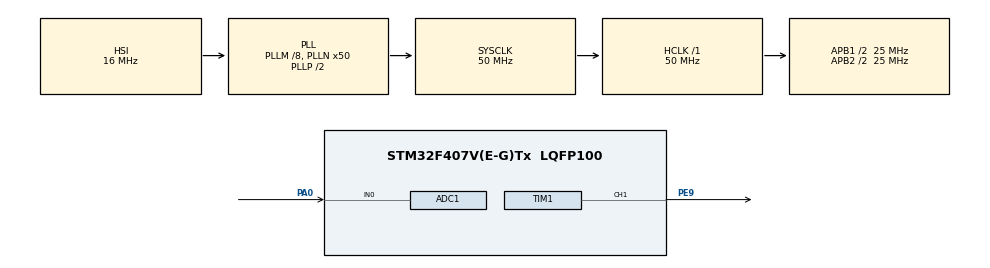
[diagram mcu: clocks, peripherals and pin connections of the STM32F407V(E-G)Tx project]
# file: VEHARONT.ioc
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ADC1.Channel-5\#ChannelRegularConversion=ADC_CHANNEL_0
ADC1.NbrOfConversionFlag=1
ADC1.Rank-5\#ChannelRegularConversion=1
ADC1.SamplingTime-5\#ChannelRegularConversion=ADC_SAMPLETIME_3CYCLES
ADC1.master=1
Mcu.Family=STM32F4
Mcu.Name=STM32F407V(E-G)Tx
Mcu.Package=LQFP100
NVIC.PriorityGroup=NVIC_PRIORITYGROUP_0
PA0-WKUP.Signal=ADCx_IN0
PE9.Signal=S_TIM1_CH1
ProjectManager.HeapSize=0x200
ProjectManager.StackSize=0x400
ProjectManager.TargetToolchain=STM32CubeIDE
RCC.48MHZClocksFreq_Value=14285714.285714285
RCC.AHBFreq_Value=50000000
RCC.APB1CLKDivider=RCC_HCLK_DIV2
RCC.APB1Freq_Value=25000000
RCC.APB1TimFreq_Value=50000000
RCC.APB2CLKDivider=RCC_HCLK_DIV2
RCC.APB2Freq_Value=25000000
RCC.APB2TimFreq_Value=50000000
RCC.CortexFreq_Value=50000000
RCC.HCLKFreq_Value=50000000
RCC.HSE_VALUE=8000000
RCC.HSI_VALUE=16000000
RCC.LSE_VALUE=32768
RCC.PLLM=8
RCC.PLLN=50
RCC.PLLQ=7
RCC.SYSCLKFreq_VALUE=50000000
RCC.SYSCLKSource=RCC_SYSCLKSOURCE_PLLCLK
RCC.VCOOutputFreq_Value=100000000
SH.ADCx_IN0.0=ADC1_IN0,IN0
SH.S_TIM1_CH1.0=TIM1_CH1,PWM Generation1 CH1
TIM1.Channel-PWM\ Generation1\ CH1=TIM_CHANNEL_1
TIM1.Period=5-1
TIM1.Prescaler=1-1
VP_TIM1_VS_ClockSourceINT.Mode=Internal
board=STM32F407G-DISC1

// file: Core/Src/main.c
/* USER CODE BEGIN Header */
/**
  ******************************************************************************
  * @file           : main.c
  * @brief          : Main program body
  ******************************************************************************
  * @attention
  *
  * <h2><center>&copy; Copyright (c) 2021 STMicroelectronics.
  * All rights reserved.</center></h2>
  *
  * This software component is licensed by ST under BSD 3-Clause license,
  * the "License"; You may not use this file except in compliance with the
  * License. You may obtain a copy of the License at:
  *                        opensource.org/licenses/BSD-3-Clause
  *
  ******************************************************************************
  */
/* USER CODE END Header */
#include "main.h"

/* USER CODE BEGIN Includes */
#include "keys.h"
#include <stdio.h>
#include <string.h>
#include <stdlib.h>
#include <math.h>
/* USER CODE END Includes */

/* USER CODE BEGIN PD */
#define FLOAT_TO_INT(x) ((x)>=0?(int)((x)+0.5):(int)((x)-0.5))
#define R1 92.1
#define R2 9.86
#define R3 260
/* USER CODE END PD */

ADC_HandleTypeDef hadc1;

TIM_HandleTypeDef htim1;

/* USER CODE BEGIN PV */

char keyarr[3] = {0,0};
unsigned long last = 0;  // the last time the output pin was toggled
unsigned long delay = 200;    // the debounce time; increase if the output flickers
int voltage_level_measured = 0;
int voltage_setpoint = 0;
/* USER CODE END PV */

void SystemClock_Config(void);
static void MX_GPIO_Init(void);
static void MX_ADC1_Init(void);
static void MX_TIM1_Init(void);

/* USER CODE BEGIN 0 */
char convert(int keys){
	switch(keys){
		case 1: return 1; break;
		case 2: return 2; break;
		case 3: return 3; break;
		case 4: return 'A'; break;
		case 5: return 4; break;
		case 6: return 5; break;
		case 7: return 6; break;
		case 8: return 'B'; break;
		case 9: return 7; break;
		case 10: return 8; break;
		case 11: return 9; break;
		case 12: return 'C'; break;
		case 13: return '*'; break;
		case 14: return 0; break;
		case 15: return '#'; break;
		case 16: return 'D'; break;
		default: return 0; break;
	}
	return 0;
}

float decimal(char num){
	switch(num){
		case 1: return 0.1f; break;
		case 2: return 0.2f; break;
		case 3: return 0.3f; break;
		case 4: return 0.4f; break;
		case 5: return 0.5f; break;
		case 6: return 0.6f; break;
		case 7: return 0.7f; break;
		case 8: return 0.8f; break;
		case 9: return 0.9f; break;
		default: return 0; break;
	}
	return 0;
}
void V_TO_ADC(float voltage_set){
	float Rtot = ((float)(R2*R3)/(float)(R3+R2));
	float voltage = ((voltage_set) * Rtot)/(Rtot + R1);
	voltage_setpoint = FLOAT_TO_INT((voltage * 4096)/3.20);
}

void set_voltage_level(){
	HAL_ADC_Start(&hadc1);
	HAL_ADC_PollForConversion(&hadc1, 10);
	voltage_level_measured = HAL_ADC_GetValue(&hadc1);
	if(voltage_level_measured < voltage_setpoint){
		if(TIM1->CCR1 < 200){
		TIM1->CCR1++;
		}
	}
	else if(voltage_level_measured > voltage_setpoint){
		if(TIM1->CCR1 > 10){
		TIM1->CCR1--;
		}
	}
}
/* USER CODE END 0 */

int main(void)
{

  /* MCU Configuration--------------------------------------------------------*/

  /* Reset of all peripherals, Initializes the Flash interface and the Systick. */
  HAL_Init();

  /* USER CODE BEGIN Init */
  KEYS_init();
  /* USER CODE END Init */

  /* Configure the system clock */
  SystemClock_Config();

  /* Initialize all configured peripherals */
  MX_GPIO_Init();
  MX_ADC1_Init();
  MX_TIM1_Init();
  /* USER CODE BEGIN 2 */
  //R1 = 92K
  //R2 = 10K
  //Value = (Vin/10)/4096
  //557 = 5V
  V_TO_ADC(5);
  TIM1->CCR1 = 84;
  HAL_TIM_PWM_Start(&htim1, TIM_CHANNEL_1);
  int keys = 0;
  int i =0;
  float voltage_set = 0;
  /* USER CODE END 2 */

  /* Infinite loop */
  /* USER CODE BEGIN WHILE */
  while (1)
  {

	 keys = KEYS_read();
	 if((HAL_GetTick() - last) > delay){
		 if(keys != 0 && keys != keyarr[i]){
		   keyarr[i] = convert(keys);
		   if(i == 0){
			   voltage_set = (float)keyarr[i];
		   }
		   if(i == 1){
			   voltage_set += decimal(keyarr[i]);
		   }
		   if(keyarr[i] == '#'){
			   memset(keyarr, 0, 3);
			   i=0;
		   }
		   if(i == 2 && keyarr[2] == 'A'){

			   V_TO_ADC(voltage_set);
		   }
		   if(i == 2){ i = 0;  memset(keyarr, 0, 3);}
		   else i++;
		   last = HAL_GetTick();
		 }
	 }
	 set_voltage_level();
    /* USER CODE END WHILE */

  }
}

void SystemClock_Config(void)
{
  RCC_OscInitTypeDef RCC_OscInitStruct = {0};
  RCC_ClkInitTypeDef RCC_ClkInitStruct = {0};

  /** Configure the main internal regulator output voltage
  */
  __HAL_RCC_PWR_CLK_ENABLE();
  __HAL_PWR_VOLTAGESCALING_CONFIG(PWR_REGULATOR_VOLTAGE_SCALE1);
  /** Initializes the RCC Oscillators according to the specified parameters
  * in the RCC_OscInitTypeDef structure.
  */
  RCC_OscInitStruct.OscillatorType = RCC_OSCILLATORTYPE_HSI;
  RCC_OscInitStruct.HSIState = RCC_HSI_ON;
  RCC_OscInitStruct.HSICalibrationValue = RCC_HSICALIBRATION_DEFAULT;
  RCC_OscInitStruct.PLL.PLLState = RCC_PLL_ON;
  RCC_OscInitStruct.PLL.PLLSource = RCC_PLLSOURCE_HSI;
  RCC_OscInitStruct.PLL.PLLM = 8;
  RCC_OscInitStruct.PLL.PLLN = 50;
  RCC_OscInitStruct.PLL.PLLP = RCC_PLLP_DIV2;
  RCC_OscInitStruct.PLL.PLLQ = 7;
  if (HAL_RCC_OscConfig(&RCC_OscInitStruct) != HAL_OK)
  {
    Error_Handler();
  }
  /** Initializes the CPU, AHB and APB buses clocks
  */
  RCC_ClkInitStruct.ClockType = RCC_CLOCKTYPE_HCLK|RCC_CLOCKTYPE_SYSCLK
                              |RCC_CLOCKTYPE_PCLK1|RCC_CLOCKTYPE_PCLK2;
  RCC_ClkInitStruct.SYSCLKSource = RCC_SYSCLKSOURCE_PLLCLK;
  RCC_ClkInitStruct.AHBCLKDivider = RCC_SYSCLK_DIV1;
  RCC_ClkInitStruct.APB1CLKDivider = RCC_HCLK_DIV2;
  RCC_ClkInitStruct.APB2CLKDivider = RCC_HCLK_DIV2;

  if (HAL_RCC_ClockConfig(&RCC_ClkInitStruct, FLASH_LATENCY_1) != HAL_OK)
  {
    Error_Handler();
  }
}

static void MX_ADC1_Init(void)
{

  ADC_ChannelConfTypeDef sConfig = {0};

  /** Configure the global features of the ADC (Clock, Resolution, Data Alignment and number of conversion)
  */
  hadc1.Instance = ADC1;
  hadc1.Init.ClockPrescaler = ADC_CLOCK_SYNC_PCLK_DIV2;
  hadc1.Init.Resolution = ADC_RESOLUTION_12B;
  hadc1.Init.ScanConvMode = DISABLE;
  hadc1.Init.ContinuousConvMode = DISABLE;
  hadc1.Init.DiscontinuousConvMode = DISABLE;
  hadc1.Init.ExternalTrigConvEdge = ADC_EXTERNALTRIGCONVEDGE_NONE;
  hadc1.Init.ExternalTrigConv = ADC_SOFTWARE_START;
  hadc1.Init.DataAlign = ADC_DATAALIGN_RIGHT;
  hadc1.Init.NbrOfConversion = 1;
  hadc1.Init.DMAContinuousRequests = DISABLE;
  hadc1.Init.EOCSelection = ADC_EOC_SINGLE_CONV;
  if (HAL_ADC_Init(&hadc1) != HAL_OK)
  {
    Error_Handler();
  }
  /** Configure for the selected ADC regular channel its corresponding rank in the sequencer and its sample time.
  */
  sConfig.Channel = ADC_CHANNEL_0;
  sConfig.Rank = 1;
  sConfig.SamplingTime = ADC_SAMPLETIME_3CYCLES;
  if (HAL_ADC_ConfigChannel(&hadc1, &sConfig) != HAL_OK)
  {
    Error_Handler();
  }

}

static void MX_TIM1_Init(void)
{

  TIM_ClockConfigTypeDef sClockSourceConfig = {0};
  TIM_MasterConfigTypeDef sMasterConfig = {0};
  TIM_OC_InitTypeDef sConfigOC = {0};
  TIM_BreakDeadTimeConfigTypeDef sBreakDeadTimeConfig = {0};

  htim1.Instance = TIM1;
  htim1.Init.Prescaler = 1-1;
  htim1.Init.CounterMode = TIM_COUNTERMODE_UP;
  htim1.Init.Period = 250-1;
  htim1.Init.ClockDivision = TIM_CLOCKDIVISION_DIV1;
  htim1.Init.RepetitionCounter = 0;
  htim1.Init.AutoReloadPreload = TIM_AUTORELOAD_PRELOAD_DISABLE;
  if (HAL_TIM_Base_Init(&htim1) != HAL_OK)
  {
    Error_Handler();
  }
  sClockSourceConfig.ClockSource = TIM_CLOCKSOURCE_INTERNAL;
  if (HAL_TIM_ConfigClockSource(&htim1, &sClockSourceConfig) != HAL_OK)
  {
    Error_Handler();
  }
  if (HAL_TIM_PWM_Init(&htim1) != HAL_OK)
  {
    Error_Handler();
  }
  sMasterConfig.MasterOutputTrigger = TIM_TRGO_RESET;
  sMasterConfig.MasterSlaveMode = TIM_MASTERSLAVEMODE_DISABLE;
  if (HAL_TIMEx_MasterConfigSynchronization(&htim1, &sMasterConfig) != HAL_OK)
  {
    Error_Handler();
  }
  sConfigOC.OCMode = TIM_OCMODE_PWM1;
  sConfigOC.Pulse = 0;
  sConfigOC.OCPolarity = TIM_OCPOLARITY_HIGH;
  sConfigOC.OCNPolarity = TIM_OCNPOLARITY_HIGH;
  sConfigOC.OCFastMode = TIM_OCFAST_DISABLE;
  sConfigOC.OCIdleState = TIM_OCIDLESTATE_RESET;
  sConfigOC.OCNIdleState = TIM_OCNIDLESTATE_RESET;
  if (HAL_TIM_PWM_ConfigChannel(&htim1, &sConfigOC, TIM_CHANNEL_1) != HAL_OK)
  {
    Error_Handler();
  }
  sBreakDeadTimeConfig.OffStateRunMode = TIM_OSSR_DISABLE;
  sBreakDeadTimeConfig.OffStateIDLEMode = TIM_OSSI_DISABLE;
  sBreakDeadTimeConfig.LockLevel = TIM_LOCKLEVEL_OFF;
  sBreakDeadTimeConfig.DeadTime = 0;
  sBreakDeadTimeConfig.BreakState = TIM_BREAK_DISABLE;
  sBreakDeadTimeConfig.BreakPolarity = TIM_BREAKPOLARITY_HIGH;
  sBreakDeadTimeConfig.AutomaticOutput = TIM_AUTOMATICOUTPUT_DISABLE;
  if (HAL_TIMEx_ConfigBreakDeadTime(&htim1, &sBreakDeadTimeConfig) != HAL_OK)
  {
    Error_Handler();
  }
  HAL_TIM_MspPostInit(&htim1);

}

static void MX_GPIO_Init(void)
{

  /* GPIO Ports Clock Enable */
  __HAL_RCC_GPIOA_CLK_ENABLE();
  __HAL_RCC_GPIOE_CLK_ENABLE();

}

void Error_Handler(void)
{
  __disable_irq();
  while (1)
  {
  }
}

/************************ (C) COPYRIGHT STMicroelectronics *****END OF FILE****/
